# neorv32 register map
Vendor: github.com/stnolting/neorv32; Series: RISC-V; File version: 1.13.7
CPU: other r1p0, little endian, MPU, FPU, I-cache, D-cache, ITCM, DTCM, 4 interrupt priority bits
Address unit: 16 bits
Registers are 32-bit, read-write, reset 0x0 unless marked. A register's access mark holds for its fields unless they carry their own. Offsets are from the block's base; [hi:lo] are bit positions; lines under a group give offsets from that group; {n}, {i} and the like mark numbered series.

## DMA — Direct memory access controller
Base 0xFFED0000
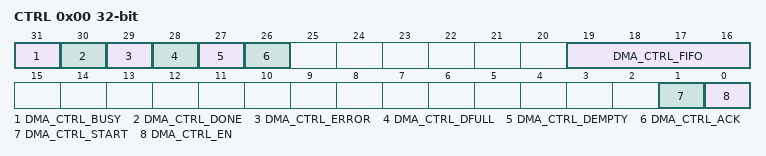
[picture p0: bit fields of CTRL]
0x00 CTRL — Control and status register
  [31] DMA_CTRL_BUSY ro — Transfer(s) in progress
  [30] DMA_CTRL_DONE ro — Transfer(s) done
  [29] DMA_CTRL_ERROR ro — Error during last transfer
  [28] DMA_CTRL_DFULL ro — Descriptor FIFO is full
  [27] DMA_CTRL_DEMPTY ro — Descriptor FIFO is empty
  [26] DMA_CTRL_ACK wo — Write 1 to clear ERROR and DONE flags
  [19:16] DMA_CTRL_FIFO ro — log2(descriptor FIFO depth)
  [1] DMA_CTRL_START wo — Start programmed DMA transfer(s)
  [0] DMA_CTRL_EN — DMA enable flag
0x04 DESC wo — Descriptor FIFO

## PWM — Pulse-width modulation controller
Base 0xFFF00000
0x00 ENABLE — Channel enable
0x04 POLARITY — Channel polarity
0x08 CLKPRSC — Clock prescaler select
0x0C MODE — Channel operation mode (0 = fast-PWM; 1 = phase-correct PWM)
{0x80+4i} CHANNEL[{i}] (i=0..31) group — Channel configuration register
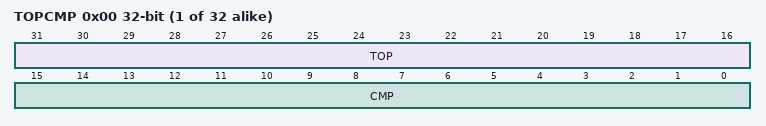
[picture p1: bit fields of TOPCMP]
  0x00 TOPCMP — Channel counter full word access alias
    [31:16] TOP — Channel counter top/wrap value
    [15:0] CMP — Channel counter compare value

## GPTMR — General purpose timer
Base 0xFFF10000
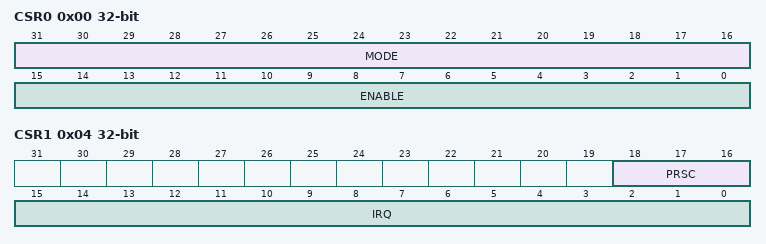
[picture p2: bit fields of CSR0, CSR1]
0x00 CSR0 — Control and status register 0
  [31:16] MODE — Per-slice mode bit (0 = single-shot mode, 1 = continuous mode)
  [15:0] ENABLE — Per-slice enable bit
0x04 CSR1 — Control and status register 1
  [18:16] PRSC — Global clock prescaler select
  [15:0] IRQ — Per-slice interrupt-pending bit; write 0 to clear
{0x80+8i} SLICE[{i}] (i=0..15) group — Timer slice
  0x00 CNT — Counter register
  0x04 THR — Threshold register

## ONEWIRE — 1-Wire Interface Controller
Base 0xFFF20000
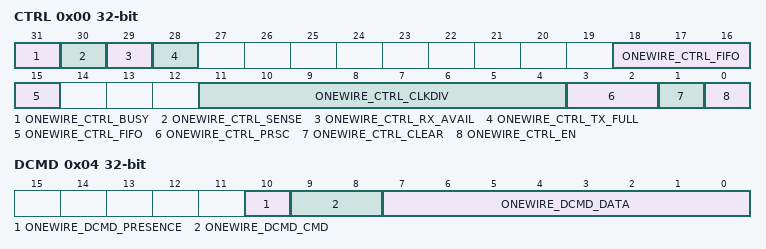
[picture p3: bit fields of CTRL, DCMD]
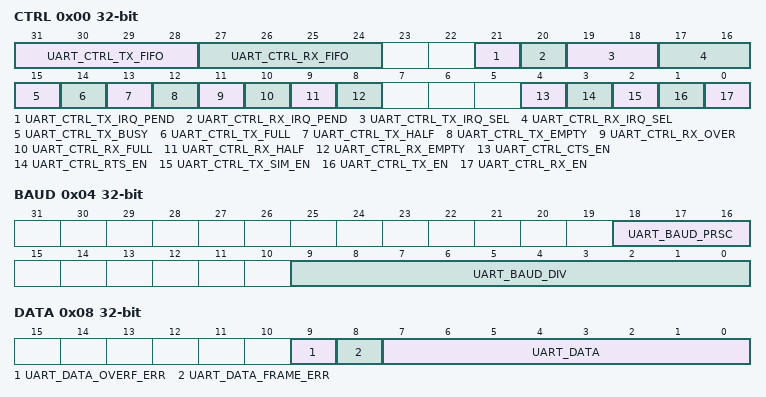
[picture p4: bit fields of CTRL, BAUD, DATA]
0x00 CTRL — Control register
  [31] ONEWIRE_CTRL_BUSY ro — Operation in progress when set
  [30] ONEWIRE_CTRL_SENSE ro — Current state of the 1-wire bus line
  [29] ONEWIRE_CTRL_RX_AVAIL ro — RX FIFO data available
  [28] ONEWIRE_CTRL_TX_FULL ro — TX FIFO full
  [18:15] ONEWIRE_CTRL_FIFO ro — log2(ONEWIRE FIFO size)
  [11:4] ONEWIRE_CTRL_CLKDIV — Clock divider
  [3:2] ONEWIRE_CTRL_PRSC — Clock prescaler select
  [1] ONEWIRE_CTRL_CLEAR wo — Clear RXT FIFO, auto-clears
  [0] ONEWIRE_CTRL_EN — ONEWIRE controller enable
0x04 DCMD read-modifies — Read/write transmission data/command register
  [10] ONEWIRE_DCMD_PRESENCE ro — Bus presence detected
  [9:8] ONEWIRE_DCMD_CMD wo — Operation command
  [7:0] ONEWIRE_DCMD_DATA — RTX data, transmitted LSB-first

## CLINT — Core local interruptor
Base 0xFFF40000
0x00 MSWI0 — Machine software interrupt; hart 0
0x4000 MTIMECMP0_LOW — Machine timer compare low word; hart0
0x4004 MTIMECMP0_HI — Machine timer compare low word; hart0
0xBFF8 MTIME_LOW — Machine timer low word
0xBFFC MTIME_HI — Machine timer high word

## UART0 — Primary universal asynchronous receiver and transmitter
Base 0xFFF50000
Same registers: UART1 0xFFF60000
0x00 CTRL — Control register
  [31:28] UART_CTRL_TX_FIFO ro — log2(TX FIFO depth)
  [27:24] UART_CTRL_RX_FIFO ro — log2(RX FIFO depth)
  [21] UART_CTRL_TX_IRQ_PEND ro — TX interrupt pending
  [20] UART_CTRL_RX_IRQ_PEND ro — RX interrupt pending
  [19:18] UART_CTRL_TX_IRQ_SEL — TX interrupt select
  [17:16] UART_CTRL_RX_IRQ_SEL — RX interrupt select
  [15] UART_CTRL_TX_BUSY ro — Transmitter busy or TX FIFO not empty
  [14] UART_CTRL_TX_FULL ro — TX FIFO is full
  [13] UART_CTRL_TX_HALF ro — TX FIFO is is at least half full
  [12] UART_CTRL_TX_EMPTY ro — TX FIFO is empty
  [11] UART_CTRL_RX_OVER ro — RX FIFO overflow
  [10] UART_CTRL_RX_FULL ro — RX FIFO is full
  [9] UART_CTRL_RX_HALF ro — RX FIFO is at least half full
  [8] UART_CTRL_RX_EMPTY ro — RX FIFO is empty
  [4] UART_CTRL_CTS_EN — Enable TX hardware flow-control (CTS
  [3] UART_CTRL_RTS_EN — Enable RX hardware flow-control (RTS)
  [2] UART_CTRL_TX_SIM_EN — Enable TX output to simulator
  [1] UART_CTRL_TX_EN — Enable transceiver (TX)
  [0] UART_CTRL_RX_EN — Enable receiver (RX)
0x04 BAUD read-modifies — Baud rate configuration register
  [18:16] UART_BAUD_PRSC — Baud rate clock prescaler select
  [9:0] UART_BAUD_DIV — Baud rate divider
0x08 DATA read-modifies — RTX data register
  [9] UART_DATA_OVERF_ERR ro — RX FIFO overflow error, clears on read
  [8] UART_DATA_FRAME_ERR ro — RX frame error, clears on read
  [7:0] UART_DATA — Receive/transmit data

## Notices in the file
Copyright (c) NEORV32 contributors.
Copyright (c) Stephan Nolting. All rights reserved.
Licensed under the BSD-3-Clause license, see LICENSE for details.
SPDX-License-Identifier: BSD-3-Clause
